AUTOSAR XML (schema 4-0-3)
package /ComponentTypes
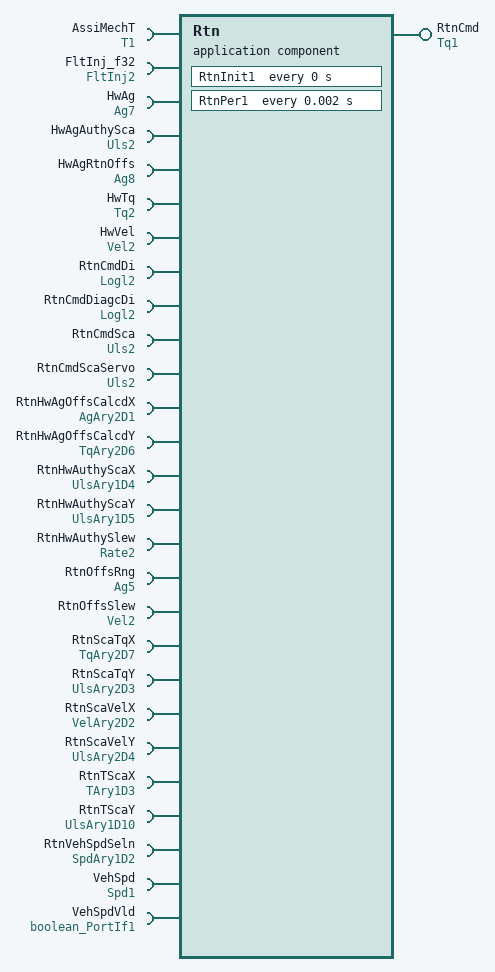
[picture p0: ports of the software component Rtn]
  application sw component type Rtn
    provide port RtnCmd: nonqueued-sender-com-spec{data-element=Val, init-value=0}, provided-interface=Tq1
    27 x require port:
      AssiMechT: nonqueued-receiver-com-spec{data-element=Val, filter=data-filter-type=ALWAYS, init-value=0}, required-interface=T1
      FltInj_f32: required-interface=FltInj2
      HwAg: nonqueued-receiver-com-spec{data-element=Val, filter=data-filter-type=ALWAYS, init-value=0}, required-interface=Ag7
      HwAgAuthySca: nonqueued-receiver-com-spec{data-element=Val, filter=data-filter-type=ALWAYS, init-value=0}, required-interface=Uls2
      HwAgRtnOffs: nonqueued-receiver-com-spec{data-element=Val, filter=data-filter-type=ALWAYS, init-value=0}, required-interface=Ag8
      HwTq: nonqueued-receiver-com-spec{data-element=Val, filter=data-filter-type=ALWAYS, init-value=0}, required-interface=Tq2
      HwVel: nonqueued-receiver-com-spec{data-element=Val, filter=data-filter-type=ALWAYS, init-value=0}, required-interface=Vel2
      RtnCmdDi: nonqueued-receiver-com-spec{data-element=Logl, filter=data-filter-type=ALWAYS, init-value=0}, required-interface=Logl2
      RtnCmdDiagcDi: nonqueued-receiver-com-spec{data-element=Logl, filter=data-filter-type=ALWAYS, init-value=0}, required-interface=Logl2
      RtnCmdSca: nonqueued-receiver-com-spec{data-element=Val, filter=data-filter-type=ALWAYS, init-value=0}, required-interface=Uls2
      RtnCmdScaServo: nonqueued-receiver-com-spec{data-element=Val, filter=data-filter-type=ALWAYS, init-value=1}, required-interface=Uls2
      RtnHwAgOffsCalcdX: parameter-require-com-spec{init-value=9 x [0, 0.5, 1, 5, 10, 20, 30, 45, 60, 90, 120, 180, 270, 360, 450, 540], parameter=Ary2D}, required-interface=AgAry2D1
      RtnHwAgOffsCalcdY: parameter-require-com-spec{init-value=9 x 16 x 0, parameter=Ary2D}, required-interface=TqAry2D6
      RtnHwAuthyScaX: parameter-require-com-spec{init-value=[0, 0.5, 0.75, 1], parameter=Ary1D}, required-interface=UlsAry1D4
      RtnHwAuthyScaY: parameter-require-com-spec{init-value=[0, 0, 0, 1], parameter=Ary1D}, required-interface=UlsAry1D5
      RtnHwAuthySlew: parameter-require-com-spec{init-value=0.5, parameter=Val}, required-interface=Rate2
      RtnOffsRng: parameter-require-com-spec{init-value=17, parameter=Val}, required-interface=Ag5
      RtnOffsSlew: parameter-require-com-spec{init-value=0.04, parameter=Val}, required-interface=Vel2
      RtnScaTqX: parameter-require-com-spec{init-value=9 x [0, 0.5, 1, 2, 3, 4, 5, 10], parameter=Ary2D}, required-interface=TqAry2D7
      RtnScaTqY: parameter-require-com-spec{init-value=9 x 8 x 1, parameter=Ary2D}, required-interface=UlsAry2D3
      RtnScaVelX: parameter-require-com-spec{init-value=9 x [0, 40, 42, 42], parameter=Ary2D}, required-interface=VelAry2D2
      RtnScaVelY: parameter-require-com-spec{init-value=9 x [1, 1, 1, 1], parameter=Ary2D}, required-interface=UlsAry2D4
      RtnTScaX: parameter-require-com-spec{init-value=[-40, -35, -30, -20, -10, 0, 10, 20, 30, 40, 50, 60, 70, 90], parameter=Ary1D}, required-interface=TAry1D3
      RtnTScaY: parameter-require-com-spec{init-value=14 x 1, parameter=Ary1D}, required-interface=UlsAry1D10
      RtnVehSpdSeln: parameter-require-com-spec{init-value=[0, 3, 7, 12, 20, 30, 45, 60, 80], parameter=Ary1D}, required-interface=SpdAry1D2
      VehSpd: nonqueued-receiver-com-spec{data-element=Val, filter=data-filter-type=ALWAYS, init-value=0}, required-interface=Spd1
      VehSpdVld: nonqueued-receiver-com-spec{data-element=Logl, filter=data-filter-type=ALWAYS, init-value=1}, required-interface=boolean_PortIf1
    behavior Rtn_InternalBehavior: data-type-mapping=Nexteer
      ar-typed-per-instance-memorys:
        9 x data, all with sw-calibration-access=READ-ONLY:
          dRtnAbsltHwAgOffsCalcd: type=Ag17
          dRtnAssiMechTRtnSca: type=Uls2
          dRtnBascRtn: type=Tq1
          dRtnHwAgAuthySca: type=Uls2
          dRtnHwAgRtnCmd: type=Tq1
          dRtnHwTqRtnSca: type=Uls2
          dRtnHwVelRtnSca: type=Uls2
          PrevHwAgAuthy: type=Uls16
          PrevHwAgOffsLimd: type=Ag16
      timing event Rtn_InitEvent: start-on-event=RtnInit1, period=0
      timing event TMT_RtnPer1: start-on-event=RtnPer1, period=0.002
      runnable RtnInit1
      runnable RtnPer1
        data-receive-point-by-arguments:
          12 x access:
            REC_AssiMechT_Val: accessed-variable=AssiMechT.Val
            REC_HwAg_Val: accessed-variable=HwAg.Val
            REC_HwAgAuthySca_Val: accessed-variable=HwAgAuthySca.Val
            REC_HwAgRtnOffs_Val: accessed-variable=HwAgRtnOffs.Val
            REC_HwTq_Val: accessed-variable=HwTq.Val
            REC_HwVel_Val: accessed-variable=HwVel.Val
            REC_RtnCmdDi_Logl: accessed-variable=RtnCmdDi.Logl
            REC_RtnCmdDiagcDi_Logl: accessed-variable=RtnCmdDiagcDi.Logl
            REC_RtnCmdSca_Val: accessed-variable=RtnCmdSca.Val
            REC_RtnCmdScaServo_Val: accessed-variable=RtnCmdScaServo.Val
            REC_VehSpd_Val: accessed-variable=VehSpd.Val
            REC_VehSpdVld_Logl: accessed-variable=VehSpdVld.Logl
        data-send-points:
          access SEND_RtnCmd_Val: accessed-variable=RtnCmd.Val
        sync call SC_FltInj_f32_Oper: operation=FltInj_f32.Oper, timeout=0
  swc implementation Rtn_Implementation: behavior=Rtn_InternalBehavior
    code-descriptors:
      code Default: artifact-descriptors=autosar-engineering-object={short-label=Default, category=SWSRC}
